# nrf54h20_engb_sysctrl register map
Vendor: Nordic Semiconductor; Series: nRF54h; File version: 1
Registers are 32-bit, read-write, reset 0x0 unless marked. A register's access mark holds for its fields unless they carry their own. Offsets are from the block's base; [hi:lo] are bit positions; {n}, {i} and the like mark numbered series.

## PCGCM200 — PCGC Master 0
Base 0xBF006000
Same registers: PCGCM110 0x5F08F000, PCGCM120 0x5F8CF000, PCGCM121 0x5F8ED000, PCGCM130 0x5F93D000, PCGCM131 0x5F93F000, PCGCM132 0x5F94F000, PCGCM133 0x5F98F000, PCGCM134 0x5F99F000, PCGCM135 0x5F9AF000, PCGCM136 0x5F9BF000, PCGCM137 0x5F9CF000, PCGCM138 0x5F9DF000, PCGCM210 0xBF013000
{0xE0+4i} SETPWRCONTHRESHOLDBASE[{i}] (i=0..2) — Description collection: Set power consumption threshold base for power source / regulator n
  [3:0] SETPWRCONTHRESHOLDBASE
0xC00 UNLOCKBACKDOORS
  [15:0] UNLOCKBACKDOORS — Write: 0x00009375 to lock/unlock backdoors Read: 0x00000001 if backdoors is enabled Read: 0x00000000 if backdoors is disabled
0xC04 ENABLEPOWERREGFORCE
  [2:0] ENABLEPOWERREGFORCE
0xC08 POWERREGFORCE — Force reg
  [2:0] POWERREGFORCEREG
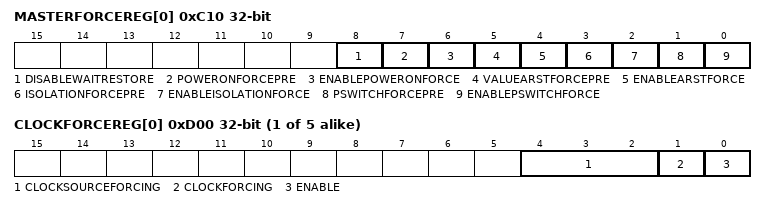
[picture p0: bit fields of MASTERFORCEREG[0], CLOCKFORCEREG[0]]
{0xC10+4i} MASTERFORCEREG[{i}] (i=0..0) — Description collection: Force reg
  [8] DISABLEWAITRESTORE — Turn off waiting for arst deactivation before retention restore
    1=Disable (Turn off waiting for arst deactivation before retention restore); 0=Enable (Wait for arst deactivation before retention restore)
  [7] POWERONFORCEPRE
  [6] ENABLEPOWERONFORCE
  [5] VALUEARSTFORCEPRE
  [4] ENABLEARSTFORCE
  [3] ISOLATIONFORCEPRE
  [2] ENABLEISOLATIONFORCE
  [1] PSWITCHFORCEPRE
  [0] ENABLEPSWITCHFORCE
{0xD00+4i} CLOCKFORCEREG[{i}] (i=0..4) — Description collection: Force clock n
  [4:2] CLOCKSOURCEFORCING
  [1] CLOCKFORCING
  [0] ENABLE — Enable clock forcing

## PCGCS200 — PCGCSlave 0
Base 0xBF011000
Same registers: PCGCS110 0x5F08E000, PCGCS120 0x5F8EA000, PCGCS121 0x5F8EB000, PCGCS122 0x5F8EC000, PCGCS130 0x5F90E000, PCGCS131 0x5F93C000, PCGCS132 0x5F94E000, PCGCS133 0x5F98E000, PCGCS134 0x5F99E000, PCGCS135 0x5F9AE000, PCGCS136 0x5F9BE000, PCGCS137 0x5F9CE000, PCGCS138 0x5F9DE000
{0xC00+4i} PENALTY[{i}] (i=0..4) reset 0xFFFFFFFC — Description collection: Penalty level for power/clock pair n. When FULL_PCP_ZERO feature is not supported, PENALTY[0] address overlaps the PENALTY0 address and register description for PENALTY[0] is not valid.
  [1:0] PENALTY — Penalty level
0xC00 PENALTY0 (alternate view of PENALTY[*]) — Penalty level for power/clock pair 0. The register description is valid only when FULL_PCP_ZERO feature is not supported
  [1:0] PENALTY ro — Penalty level
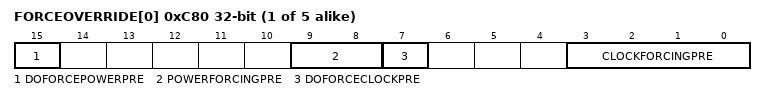
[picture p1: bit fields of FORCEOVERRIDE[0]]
{0xC80+4i} FORCEOVERRIDE[{i}] (i=0..4) — Description collection: Force override of power/clock pair n.
  [15] DOFORCEPOWERPRE, [9:8] POWERFORCINGPRE, [7] DOFORCECLOCKPRE, [3:0] CLOCKFORCINGPRE

## GLOBAL_TSGEN — Timestamp generator
Base 0xBF041000
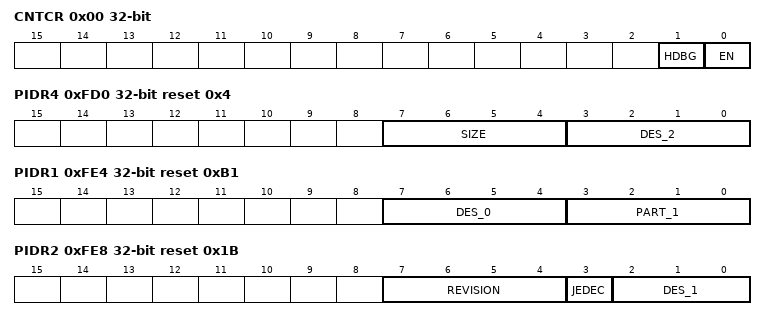
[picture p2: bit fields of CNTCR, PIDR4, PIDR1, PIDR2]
0x00 CNTCR — Counter Control Register
  [1] HDBG — Halt on Debug
    0=Disabled (Do not halt on debug, HLTDBG signal into the counter has no effect.); 1=Enabled (Halt on debug, when HLTDBG is driven HIGH, the count value is held static.)
  [0] EN — Counter enable
    0=Disabled (Unspecified); 1=Enabled (Unspecified)
0x04 CNTSR ro — Counter Status Register
  [1] DBGH — Debug halted
0x08 CNTCVL — Current Counter Value Lower register
  [31:0] CNTCVL_L_32 — Current value of Counter, lower 32 bits
0x0C CNTCVU — Current Counter Value Upper register
  [31:0] CNTCVU_U_32 — Current value of Counter, upper 32 bits
0x20 CNTFID0 — Base Frequency ID
  [31:0] FREQ — Frequency in number of ticks per second (up to 4 GHz)
0xFD0 PIDR4 ro reset 0x4 — Peripheral ID4 Register
  [7:4] SIZE — This is a 4-bit value that indicates the total contiguous size of the memory window used by this component in powers of 2 from the standard 4KB. If a component only requires the standard 4KB, this must read as 0x0, 4KB only. For 8KB set to 0x1, for 16KB set to 0x2, for 32KB set to 0x3, and so on.
  [3:0] DES_2 — JEDEC continuation code indicating the designer of the component, together with the identity code.
0xFE0 PIDR0 ro reset 0x1 — Peripheral ID0 Register
  [7:0] PART_0 — Bits [7:0] of the component part number. This is selected by the designer of the component.
0xFE4 PIDR1 ro reset 0xB1 — Peripheral ID1 Register
  [7:4] DES_0 — Bits [3:0] of the JEDEC identity code indicating the designer of the component, together with the continuation code.
  [3:0] PART_1 — Bits [11:8] of the component part number. This is selected by the designer of the component.
0xFE8 PIDR2 ro reset 0x1B — Peripheral ID2 Register
  [7:4] REVISION — The Revision field is an incremental value starting at 0x0 for the first design of this component. This only increases by 1 for both major and minor revisions and is used as a look-up to establish the exact major and minor revision.
  [3] JEDEC — Always set. Indicates that a JEDEC assigned value is used.
  [2:0] DES_1 — Bits [6:4] of the JEDEC identity code indicating the designer of the component, together with the continuation code.
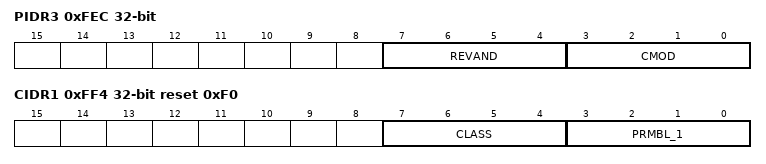
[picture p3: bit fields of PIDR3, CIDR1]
0xFEC PIDR3 ro — Peripheral ID3 Register
  [7:4] REVAND — This field indicates minor errata fixes specific to this design, for example metal fixes after implementation. In most cases this field is zero. It is recommended that component designers ensure this field can be changed by a metal fix if required, for example by driving it from registers that reset to zero.
  [3:0] CMOD — Where the component is reusable IP, this value indicates if the customer has modified the behavior of the component. In most cases this field is zero.
0xFF0 CIDR0 ro reset 0xD — Component ID0 Register
  [7:0] PRMBL_0 — Contains bits[7:0] of the component identification code.
0xFF4 CIDR1 ro reset 0xF0 — Component ID1 Register
  [7:4] CLASS — Class of the component, for example, ROM table or CoreSight component.
  [3:0] PRMBL_1 — Contains bits[11:8] of the component identification code.
0xFF8 CIDR2 ro reset 0x5 — Component ID2 Register
  [7:0] PRMBL_2 — Contains bits[23:16] of the component identification code.
0xFFC CIDR3 ro reset 0xB1 — Component ID3 Register
  [7:0] PRMBL_3 — Contains bits[31:24] of the component identification code.
